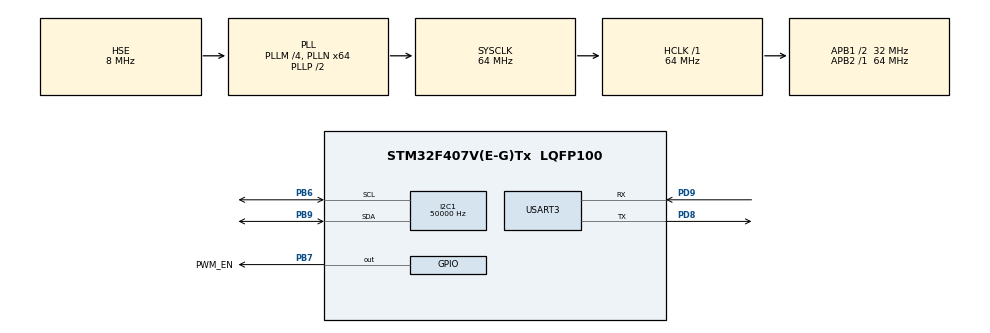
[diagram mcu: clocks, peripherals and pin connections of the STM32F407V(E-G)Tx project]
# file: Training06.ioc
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Dma.Request0=USART3_RX
Dma.USART3_RX.0.Direction=DMA_PERIPH_TO_MEMORY
Dma.USART3_RX.0.FIFOMode=DMA_FIFOMODE_DISABLE
Dma.USART3_RX.0.Instance=DMA1_Stream1
Dma.USART3_RX.0.MemDataAlignment=DMA_MDATAALIGN_BYTE
Dma.USART3_RX.0.MemInc=DMA_MINC_ENABLE
Dma.USART3_RX.0.Mode=DMA_NORMAL
Dma.USART3_RX.0.PeriphDataAlignment=DMA_PDATAALIGN_BYTE
Dma.USART3_RX.0.PeriphInc=DMA_PINC_DISABLE
Dma.USART3_RX.0.Priority=DMA_PRIORITY_LOW
I2C1.ClockSpeed=50000
Mcu.Family=STM32F4
Mcu.Name=STM32F407V(E-G)Tx
Mcu.Package=LQFP100
NVIC.DMA1_Stream1_IRQn=true\:0\:0\:true\:false\:true\:false\:true\:true
NVIC.PriorityGroup=NVIC_PRIORITYGROUP_4
NVIC.USART3_IRQn=true\:0\:0\:true\:false\:true\:true\:true\:true
PB6.Mode=I2C
PB6.Signal=I2C1_SCL
PB7.GPIO_Label=PWM_EN
PB7.PinState=GPIO_PIN_SET
PB7.Signal=GPIO_Output
PB9.Mode=I2C
PB9.Signal=I2C1_SDA
PD8.Mode=Asynchronous
PD8.Signal=USART3_TX
PD9.Mode=Asynchronous
PD9.Signal=USART3_RX
PH0-OSC_IN.Mode=HSE-External-Oscillator
PH0-OSC_IN.Signal=RCC_OSC_IN
PH1-OSC_OUT.Mode=HSE-External-Oscillator
PH1-OSC_OUT.Signal=RCC_OSC_OUT
ProjectManager.HeapSize=0x200
ProjectManager.StackSize=0x400
ProjectManager.TargetToolchain=STM32CubeIDE
RCC.48MHZClocksFreq_Value=32000000
RCC.AHBFreq_Value=64000000
RCC.APB1CLKDivider=RCC_HCLK_DIV2
RCC.APB1Freq_Value=32000000
RCC.APB1TimFreq_Value=64000000
RCC.APB2Freq_Value=64000000
RCC.APB2TimFreq_Value=64000000
RCC.CortexFreq_Value=64000000
RCC.HCLKFreq_Value=64000000
RCC.HSE_VALUE=8000000
RCC.HSI_VALUE=16000000
RCC.LSE_VALUE=32768
RCC.PLLM=4
RCC.PLLN=64
RCC.PLLSourceVirtual=RCC_PLLSOURCE_HSE
RCC.SYSCLKFreq_VALUE=64000000
RCC.SYSCLKSource=RCC_SYSCLKSOURCE_PLLCLK
RCC.VCOOutputFreq_Value=128000000
USART3.VirtualMode=VM_ASYNC
board=custom

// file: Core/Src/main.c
/* USER CODE BEGIN Header */
/**
  ******************************************************************************
  * @file           : main.c
  * @brief          : Main program body
  ******************************************************************************
  * @attention
  *
  * Copyright (c) 2023 STMicroelectronics.
  * All rights reserved.
  *
  * This software is licensed under terms that can be found in the LICENSE file
  * in the root directory of this software component.
  * If no LICENSE file comes with this software, it is provided AS-IS.
  *
  ******************************************************************************
  */
/* USER CODE END Header */
#include "main.h"

/* USER CODE BEGIN Includes */
#include "PCA9685.h"
/* USER CODE END Includes */

I2C_HandleTypeDef hi2c1;

UART_HandleTypeDef huart3;
DMA_HandleTypeDef hdma_usart3_rx;

void SystemClock_Config(void);
static void MX_GPIO_Init(void);
static void MX_DMA_Init(void);
static void MX_I2C1_Init(void);
static void MX_USART3_UART_Init(void);

int main(void)
{

  /* MCU Configuration--------------------------------------------------------*/

  /* Reset of all peripherals, Initializes the Flash interface and the Systick. */
  HAL_Init();

  /* Configure the system clock */
  SystemClock_Config();

  /* Initialize all configured peripherals */
  MX_GPIO_Init();
  MX_DMA_Init();
  MX_I2C1_Init();
  MX_USART3_UART_Init();

  /* Infinite loop */
  /* USER CODE BEGIN WHILE */
  HAL_Delay(10);
  PCA9685_LedStateWhenDisabled(OFF);
  PCA9685_SleepMode(OFF); //Normal Mode
  PCA9685_Enable(ON);

  PollUart();
  while (1)
  {

	  HAL_Delay(200);
	  //PollUart();
	  HandleUartData();

/*
for (uint32_t i=0;i<12;i++)
{
	for (uint32_t j=0;j<16;j++)
	  {SetLedAlt(j, i);} //number=0...15, brightness =0...100;

	  HAL_Delay(200);

}
*/

    /* USER CODE END WHILE */

  }
}

void SystemClock_Config(void)
{
  RCC_OscInitTypeDef RCC_OscInitStruct = {0};
  RCC_ClkInitTypeDef RCC_ClkInitStruct = {0};

  /** Configure the main internal regulator output voltage
  */
  __HAL_RCC_PWR_CLK_ENABLE();
  __HAL_PWR_VOLTAGESCALING_CONFIG(PWR_REGULATOR_VOLTAGE_SCALE1);

  /** Initializes the RCC Oscillators according to the specified parameters
  * in the RCC_OscInitTypeDef structure.
  */
  RCC_OscInitStruct.OscillatorType = RCC_OSCILLATORTYPE_HSE;
  RCC_OscInitStruct.HSEState = RCC_HSE_ON;
  RCC_OscInitStruct.PLL.PLLState = RCC_PLL_ON;
  RCC_OscInitStruct.PLL.PLLSource = RCC_PLLSOURCE_HSE;
  RCC_OscInitStruct.PLL.PLLM = 4;
  RCC_OscInitStruct.PLL.PLLN = 64;
  RCC_OscInitStruct.PLL.PLLP = RCC_PLLP_DIV2;
  RCC_OscInitStruct.PLL.PLLQ = 4;
  if (HAL_RCC_OscConfig(&RCC_OscInitStruct) != HAL_OK)
  {
    Error_Handler();
  }

  /** Initializes the CPU, AHB and APB buses clocks
  */
  RCC_ClkInitStruct.ClockType = RCC_CLOCKTYPE_HCLK|RCC_CLOCKTYPE_SYSCLK
                              |RCC_CLOCKTYPE_PCLK1|RCC_CLOCKTYPE_PCLK2;
  RCC_ClkInitStruct.SYSCLKSource = RCC_SYSCLKSOURCE_PLLCLK;
  RCC_ClkInitStruct.AHBCLKDivider = RCC_SYSCLK_DIV1;
  RCC_ClkInitStruct.APB1CLKDivider = RCC_HCLK_DIV2;
  RCC_ClkInitStruct.APB2CLKDivider = RCC_HCLK_DIV1;

  if (HAL_RCC_ClockConfig(&RCC_ClkInitStruct, FLASH_LATENCY_2) != HAL_OK)
  {
    Error_Handler();
  }
}

static void MX_I2C1_Init(void)
{

  hi2c1.Instance = I2C1;
  hi2c1.Init.ClockSpeed = 50000;
  hi2c1.Init.DutyCycle = I2C_DUTYCYCLE_2;
  hi2c1.Init.OwnAddress1 = 0;
  hi2c1.Init.AddressingMode = I2C_ADDRESSINGMODE_7BIT;
  hi2c1.Init.DualAddressMode = I2C_DUALADDRESS_DISABLE;
  hi2c1.Init.OwnAddress2 = 0;
  hi2c1.Init.GeneralCallMode = I2C_GENERALCALL_DISABLE;
  hi2c1.Init.NoStretchMode = I2C_NOSTRETCH_DISABLE;
  if (HAL_I2C_Init(&hi2c1) != HAL_OK)
  {
    Error_Handler();
  }

}

static void MX_USART3_UART_Init(void)
{

  huart3.Instance = USART3;
  huart3.Init.BaudRate = 115200;
  huart3.Init.WordLength = UART_WORDLENGTH_8B;
  huart3.Init.StopBits = UART_STOPBITS_1;
  huart3.Init.Parity = UART_PARITY_NONE;
  huart3.Init.Mode = UART_MODE_TX_RX;
  huart3.Init.HwFlowCtl = UART_HWCONTROL_NONE;
  huart3.Init.OverSampling = UART_OVERSAMPLING_16;
  if (HAL_UART_Init(&huart3) != HAL_OK)
  {
    Error_Handler();
  }

}

static void MX_DMA_Init(void)
{

  /* DMA controller clock enable */
  __HAL_RCC_DMA1_CLK_ENABLE();

  /* DMA interrupt init */
  /* DMA1_Stream1_IRQn interrupt configuration */
  HAL_NVIC_SetPriority(DMA1_Stream1_IRQn, 0, 0);
  HAL_NVIC_EnableIRQ(DMA1_Stream1_IRQn);

}

static void MX_GPIO_Init(void)
{
  GPIO_InitTypeDef GPIO_InitStruct = {0};

  /* GPIO Ports Clock Enable */
  __HAL_RCC_GPIOH_CLK_ENABLE();
  __HAL_RCC_GPIOD_CLK_ENABLE();
  __HAL_RCC_GPIOB_CLK_ENABLE();

  /*Configure GPIO pin Output Level */
  HAL_GPIO_WritePin(PWM_EN_GPIO_Port, PWM_EN_Pin, GPIO_PIN_SET);

  /*Configure GPIO pin : PWM_EN_Pin */
  GPIO_InitStruct.Pin = PWM_EN_Pin;
  GPIO_InitStruct.Mode = GPIO_MODE_OUTPUT_PP;
  GPIO_InitStruct.Pull = GPIO_NOPULL;
  GPIO_InitStruct.Speed = GPIO_SPEED_FREQ_LOW;
  HAL_GPIO_Init(PWM_EN_GPIO_Port, &GPIO_InitStruct);

}

void Error_Handler(void)
{
  __disable_irq();
  while (1)
  {
  }
}
